# STM32MP25_CM33 register map
File version: 1.3
CPU: CM33 r0p1, little endian, MPU, FPU, vendor SysTick, 8 interrupt priority bits
Registers are 32-bit, read-write, reset 0x0 unless marked. A register's access mark holds for its fields unless they carry their own. Offsets are from the block's base; [hi:lo] are bit positions; lines under a group give offsets from that group; {n}, {i} and the like mark numbered series; 'fields as' and 'values as' point back to an identical list.

## ADC1 — ADC register block
Base 0x404E0000
Same registers: ADC2 0x404E0100, ADC1_S 0x504E0000, ADC2_S 0x504E0100
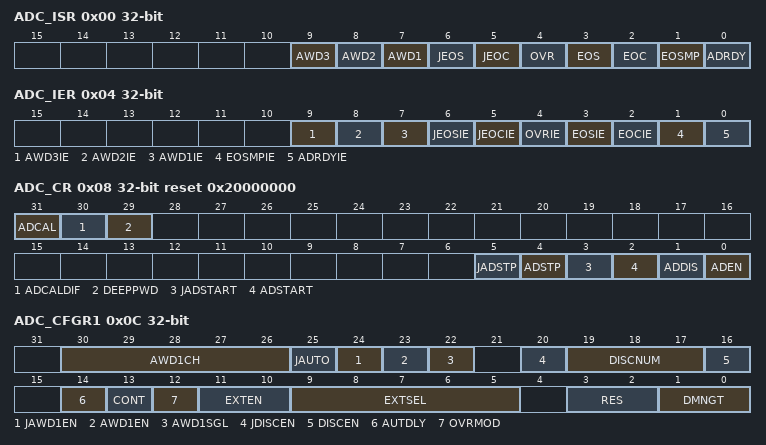
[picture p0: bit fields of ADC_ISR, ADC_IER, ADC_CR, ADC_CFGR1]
0x00 ADC_ISR — ADC interrupt and status register
  [9] AWD3 — Analog watchdog 3 flag This bit is set by hardware when the converted voltage crosses the values programmed in the fields LTR[22:0] and HTR[22:0] of ADC_AWD3LTR and ADC_AWD3HTR registers. It is cleared by software writing 1 to it.
    0=No analog watchdog 3 event occurred (or the flag event was already acknowledged and cleared by software); 1=Analog watchdog 3 event occurred
  [8] AWD2 — Analog watchdog 2 flag This bit is set by hardware when the converted voltage crosses the values programmed in the fields LTR[22:0] and HTR[22:0] of ADC_AWD2LTR and ADC_AWD2HTR registers. It is cleared by software writing 1 to it.
    0=No analog watchdog 2 event occurred (or the flag event was already acknowledged and cleared by software); 1=Analog watchdog 2 event occurred
  [7] AWD1 — Analog watchdog 1 flag This bit is set by hardware when the converted voltage crosses the values programmed in the fields LTR[22:0] and HTR[22:0] of ADC_AWD1LTR and ADC_AWD1HTR registers. It is cleared by software. writing 1 to it.
    0=No analog watchdog 1 event occurred (or the flag event was already acknowledged and cleared by software); 1=Analog watchdog 1 event occurred
  [6] JEOS — Injected channel end of sequence flag This bit is set by hardware at the end of the conversions of all injected channels in the group. It is cleared by software writing 1 to it.
    0=Injected conversion sequence not complete (or the flag event was already acknowledged and cleared by software); 1=Injected conversions complete
  [5] JEOC — Injected channel end of conversion flag This bit is set by hardware at the end of each injected conversion of a channel when a new data is available in the corresponding ADC_JDRy register. It is cleared by software writing 1 to it, or by reading the corresponding ADC_JDRy register
    0=Injected channel conversion not complete (or the flag event was already acknowledged and cleared by software); 1=Injected channel conversion complete
  [4] OVR — ADC overrun This bit is set by hardware when an overrun occurs on a regular channel (a new conversion has completed while the EOC flag was already set) or when adc_hclk clock is too slow to manage the data. It is cleared by software writing 1 to it.
    0=No overrun occurred (or the flag event was already acknowledged and cleared by software); 1=Overrun has occurred
  [3] EOS — End of regular sequence flag This bit is set by hardware at the end of the conversions of a regular sequence of channels. It is cleared by software writing 1 to it.
    0=Regular Conversions sequence not complete (or the flag event was already acknowledged and cleared by software); 1=Regular Conversions sequence complete
  [2] EOC — End of conversion flag This bit is set by hardware at the end of each regular conversion of a channel when a new data is available in the ADC_DR register. It is cleared by software writing 1 to it or by reading the ADC_DR register
    0=Regular channel conversion not complete (or the flag event was already acknowledged and cleared by software); 1=Regular channel conversion complete
  [1] EOSMP — End of sampling flag This bit is set by hardware during the conversion of any channel (only for regular channels), at the end of the sampling phase. Note: When the OVR flag is raised, the EOSMP flag is not generated correctly.
    0=not at the end of the sampling phase (or the flag event was already acknowledged and cleared by software); 1=End of sampling phase reached
  [0] ADRDY — ADC ready This bit is set by hardware after the ADC has been enabled (bit ADEN=1) and when the ADC reaches a state where it is ready to accept conversion requests. It is cleared by software writing 1 to it.
    0=ADC not yet ready to start conversion (or the flag event was already acknowledged and cleared by software); 1=ADC is ready to start conversion
0x04 ADC_IER — ADC interrupt enable register
  [9] AWD3IE — Analog watchdog 3 interrupt enable This bit is set and cleared by software to enable/disable the analog watchdog 2 interrupt. Note: The software is allowed to write this bit only when ADSTART=0 and JADSTART=0 (which ensures that no conversion is ongoing).
    0=Analog watchdog 3 interrupt disabled; 1=Analog watchdog 3 interrupt enabled
  [8] AWD2IE — Analog watchdog 2 interrupt enable This bit is set and cleared by software to enable/disable the analog watchdog 2 interrupt. Note: The software is allowed to write this bit only when ADSTART=0 and JADSTART=0 (which ensures that no conversion is ongoing).
    0=Analog watchdog 2 interrupt disabled; 1=Analog watchdog 2 interrupt enabled
  [7] AWD1IE — Analog watchdog 1 interrupt enable This bit is set and cleared by software to enable/disable the analog watchdog 1 interrupt. Note: The software is allowed to write this bit only when ADSTART=0 and JADSTART=0 (which ensures that no conversion is ongoing).
    0=Analog watchdog 1 interrupt disabled; 1=Analog watchdog 1 interrupt enabled
  [6] JEOSIE — End of injected sequence of conversions interrupt enable This bit is set and cleared by software to enable/disable the end of injected sequence of conversions interrupt. Note: The software is allowed to write this bit only when JADSTART=0 (which ensures that no injected conversion is ongoing).
    0=JEOS interrupt disabled; 1=JEOS interrupt enabled. An interrupt is generated when the JEOS bit is set.
  [5] JEOCIE — End of injected conversion interrupt enable This bit is set and cleared by software to enable/disable the end of an injected conversion interrupt. Note: The software is allowed to write this bit only when JADSTART=0 (which ensures that no injected conversion is ongoing).
    0=JEOC interrupt disabled; 1=JEOC interrupt enabled. An interrupt is generated when the JEOC bit is set.
  [4] OVRIE — Overrun interrupt enable This bit is set and cleared by software to enable/disable the Overrun interrupt of a regular conversion. Note: The software is allowed to write this bit only when ADSTART=0 (which ensures that no regular conversion is ongoing).
    0=Overrun interrupt disabled; 1=Overrun interrupt enabled. An interrupt is generated when the OVR bit is set.
  [3] EOSIE — End of regular sequence of conversions interrupt enable This bit is set and cleared by software to enable/disable the end of regular sequence of conversions interrupt. Note: The software is allowed to write this bit only when ADSTART=0 (which ensures that no regular conversion is ongoing).
    0=EOS interrupt disabled; 1=EOS interrupt enabled. An interrupt is generated when the EOS bit is set.
  [2] EOCIE — End of regular conversion interrupt enable This bit is set and cleared by software to enable/disable the end of a regular conversion interrupt. Note: The software is allowed to write this bit only when ADSTART=0 (which ensures that no regular conversion is ongoing).
    0=EOC interrupt disabled; 1=EOC interrupt enabled. An interrupt is generated when the EOC bit is set.
  [1] EOSMPIE — End of sampling flag interrupt enable for regular conversions This bit is set and cleared by software to enable/disable the end of the sampling phase interrupt for regular conversions. Note: The software is allowed to write this bit only when ADSTART=0 (which ensures that no regular conversion is ongoing).
    0=EOSMP interrupt disabled; 1=EOSMP interrupt enabled. An interrupt is generated when the EOSMP bit is set.
  [0] ADRDYIE — ADC ready interrupt enable This bit is set and cleared by software to enable/disable the ADC Ready interrupt. Note: The software is allowed to write this bit only when ADSTART=0 and JADSTART=0 (which ensures that no conversion is ongoing).
    0=ADRDY interrupt disabled; 1=ADRDY interrupt enabled. An interrupt is generated when the ADRDY bit is set.
0x08 ADC_CR reset 0x20000000 — ADC control register
  [31] ADCAL — ADC calibration This bit is set by software to enter ADC Calibration mode. Note: The software is allowed to update the calibration factor by writing ADC_CALFACT only when ADEN=1, ADCAL=1, ADSTART=0 and JADSTART=0 (ADC enabled, Calibration mode enabled and no conversion ongoing).
    0=Normal mode; 1=Calibration mode
  [30] ADCALDIF — Differential mode for calibration This bit is set and cleared by software to configure the single-ended or differential input mode for the calibration. Note: The software is allowed to write this bit only when the ADC is disabled and is not calibrating (ADCAL=0, JADSTART=0, JADSTP=0, ADSTART=0, ADSTP=0, ADDIS=0 and ADEN=0).
    0=Single-ended input calibration mode; 1=Differential input calibration mode
  [29] DEEPPWD — Deep-power-down enable This bit is set and cleared by software to put the ADC in Deep-power-down mode. Note: The software is allowed to write this bit only when the ADC is disabled (ADCAL=0 and ADEN=0).
    0=ADC not in Deep-power down; 1=ADC in Deep-power-down (default reset state)
  [5] JADSTP — ADC stop of injected conversion command This bit is set by software to stop and discard an ongoing injected conversion (JADSTP command). It is cleared by hardware when the conversion is effectively discarded and the ADC injected sequence and triggers can be reconfigured. The ADC is then ready to accept a new start of injected conversions (JADSTART command). When a software trigger is used, JADSTART bit is cleared by hardware, but JADSTP bit must be programmed to reconfigure the ADC. Note: In auto-injection mode (JAUTO=1), setting ADSTP bit aborts both regular and injected conversions (do not use JADSTP).
    0=No ADC stop injected conversion command ongoing; 1=Write 1 to stop injected conversions ongoing. Read 1 means that an ADSTP command is in progress.
  [4] ADSTP — ADC stop of regular conversion command This bit is set by software to stop and discard an ongoing regular conversion (ADSTP Command). It is cleared by hardware when the conversion is effectively discarded. and the ADC regular sequence and triggers can be re-configured. The ADC is then ready to accept a new start of regular conversions (ADSTART command). When a software trigger is used, ADSTART bit is cleared by hardware. However it is necessary to write ADSTP bit to reconfigure the ADC. Note: In auto-injection mode (JAUTO=1), setting ADSTP bit aborts both regular and injected conversions (do not use ADSTP).
    0=No ADC stop regular conversion command ongoing; 1=Write 1 to stop regular conversions ongoing. Read 1 means that an ADSTP command is in progress.
  [3] JADSTART — ADC start of injected conversion This bit is set by software to start ADC conversion of injected channels. Depending on the configuration bits JEXTEN[1:0], a conversion starts immediately (software trigger configuration) or once an injected hardware trigger event occurs (hardware trigger configuration). This bit is cleared by hardware: In single conversion mode when software trigger is selected (JEXTSEL=0x0 and JDISEN=1): at the assertion of the end of injected conversion sequence (JEOS) flag. In all cases: after the execution of the JADSTP command, at the same time that JADSTP is cleared by hardware. Note: The software is allowed to set JADSTART only when ADEN=1,ADDIS=0 and JAUTO= 0 (ADC is enabled and there is no pending request to disable the ADC). Note: In auto-injection mode (JAUTO=1), regular and auto-injected conversions are started by setting ADSTART bit (JADSTART must be kept cleared).
    0=No ADC injected conversion is ongoing; 1=Write 1 to start injected conversions. Read 1 means that the ADC is operating and eventually converting an injected channel.
  [2] ADSTART — ADC start of regular conversion This bit is set by software to start ADC conversion of regular channels. Depending on the configuration bits EXTEN[1:0], a conversion starts immediately (software trigger configuration) or once a regular hardware trigger event occurs (hardware trigger configuration). This bit is cleared by hardware: in single conversion mode when software trigger is selected (EXTSEL=0x0 and DISEN=1): at the assertion of the end of regular conversion sequence (EOS) flag. in all cases: after the execution of the ADSTP command, at the same time that ADSTP is cleared by hardware. Note: The software is allowed to set ADSTART only when ADEN=1 and ADDIS=0 (ADC is enabled and there is no pending request to disable the ADC). Note: In auto-injection mode (JAUTO=1), regular and auto-injected conversions are started by setting ADSTART bit (JADSTART must be kept cleared)
    0=No ADC regular conversion is ongoing; 1=Write 1 to start regular conversions. Read 1 means that the ADC is operating and eventually converting a regular channel.
  [1] ADDIS — ADC disable command This bit is set by software to disable the ADC (ADDIS command) and place it into power-down state (OFF state). It is cleared by hardware once the ADC is effectively disabled (ADEN is also cleared by hardware at this time). Note: The software is allowed to set ADDIS only when ADEN=1, ADDIS=0 and both ADSTART=0 and JADSTART=0 (which ensures that no conversion is ongoing).
    0=no ADDIS command ongoing; 1=Write 1 to disable the ADC. Read 1 means that an ADDIS command is in progress.
  [0] ADEN — ADC enable control This bit is set by software to enable the ADC. The ADC is effectively ready to operate once the ADRDY flag has been set. It is cleared by hardware when the ADC is disabled, after the execution of the ADDIS command. Note: The software is allowed to set ADEN only when all the bits of ADC_CR registers are cleared (ADCAL=0, JADSTART=0, ADSTART=0, ADSTP=0, ADDIS=0 and ADEN=0).
    0=ADC is disabled (OFF state); 1=Write 1 to enable the ADC
0x0C ADC_CFGR1 — ADC configuration register
  [30:26] AWD1CH — Analog watchdog 1 channel selection These bits are set and cleared by software. They select the input channel to be guarded by the analog watchdog. ..... others: reserved, must not be used Note: Some channels are not connected physically. Keep the corresponding AWD1CH[4:0] setting to the reset value. Note: The channel selected by AWD1CH must be also selected into the SQRi or JSQRi registers. Note: The software is allowed to write these bits only when ADSTART=0 and JADSTART=0 (which ensures that no conversion is ongoing).
    0=ADC analog input channel 0 monitored by AWD1; 1=ADC analog input channel 1 monitored by AWD1; 19=ADC analog input channel 19 monitored by AWD1
  [25] JAUTO — Automatic injected group conversion This bit is set and cleared by software to enable/disable automatic injected group conversion after regular group conversion. Note: The software is allowed to write this bit only when ADSTART=0 and JADSTART=0 (which ensures that no regular nor injected conversion is ongoing).
    0=Automatic injected group conversion disabled; 1=Automatic injected group conversion enabled
  [24] JAWD1EN — Analog watchdog 1 enable on injected channels This bit is set and cleared by software Note: The software is allowed to write this bit only when JADSTART=0 (which ensures that no injected conversion is ongoing).
    0=Analog watchdog 1 disabled on injected channels; 1=Analog watchdog 1 enabled on injected channels
  [23] AWD1EN — Analog watchdog 1 enable on regular channels This bit is set and cleared by software Note: The software is allowed to write this bit only when ADSTART=0 (which ensures that no regular conversion is ongoing).
    0=Analog watchdog 1 disabled on regular channels; 1=Analog watchdog 1 enabled on regular channels
  [22] AWD1SGL — Enable the watchdog 1 on a single channel or on all channels This bit is set and cleared by software to enable the analog watchdog on the channel identified by the AWD1CH[4:0] bits or on all the channels Note: The software is allowed to write these bits only when ADSTART=0 and JADSTART=0 (which ensures that no conversion is ongoing).
    0=Analog watchdog 1 enabled on all channels; 1=Analog watchdog 1 enabled on a single channel
  [20] JDISCEN — Discontinuous mode on injected channels This bit is set and cleared by software to enable/disable discontinuous mode on the injected channels of a group. Note: The software is allowed to write this bit only when JADSTART=0 (which ensures that no injected conversion is ongoing). Note: It is not possible to use auto-injection mode and discontinuous mode simultaneously: the DISCEN and JDISCEN bits must be kept cleared by software when JAUTO is set.
    0=Discontinuous mode on injected channels disabled; 1=Discontinuous mode on injected channels enabled
  [19:17] DISCNUM — Discontinuous mode channel count These bits are written by software to define the number of regular channels to be converted in discontinuous mode, after receiving an external trigger. ... Note: The software is allowed to write these bits only when ADSTART=0 (which ensures that no regular conversion is ongoing).
    0=1 channel; 1=2 channels; 7=8 channels
  [16] DISCEN — Discontinuous mode for regular channels This bit is set and cleared by software to enable/disable discontinuous mode for regular channels. Note: It is not possible to have both discontinuous mode and continuous mode enabled: DISCEN and CONT cannot both be set (DISCEN takes priority). Note: It is not possible to use auto-injection mode and discontinuous mode simultaneously: the DISCEN and JDISCEN bits must be kept cleared by software when JAUTO is set. Note: The software is allowed to write this bit only when ADSTART=0 (which ensures that no regular conversion is ongoing).
    0=Discontinuous mode for regular channels disabled; 1=Discontinuous mode for regular channels enabled
  [14] AUTDLY — Delayed conversion mode This bit is set and cleared by software to enable/disable the auto-delayed conversion mode.sup./sup Note: The software is allowed to write this bit only when ADSTART=0 and JADSTART=0 (which ensures that no conversion is ongoing).
    0=Auto-delayed conversion mode off; 1=Auto-delayed conversion mode on
  [13] CONT — Single / continuous conversion mode for regular conversions This bit is set and cleared by software. If it is set, regular conversion takes place continuously until it is cleared. Note: It is not possible to have both discontinuous mode and continuous mode enabled: DISCEN and CONT cannot both be set (DISCEN takes priority). Note: The software is allowed to write this bit only when ADSTART=0 (which ensures that no regular conversion is ongoing).
    0=Single conversion mode; 1=Continuous conversion mode
  [12] OVRMOD — Overrun mode This bit is set and cleared by software and configure the way data overrun is managed. Note: The software is allowed to write this bit only when ADSTART=0 (which ensures that no regular conversion is ongoing).
    0=ADC_DR register is preserved with the old data when an overrun is detected; 1=ADC_DR register is overwritten with the last conversion result when an overrun is detected
  [11:10] EXTEN — External trigger enable and polarity selection for regular channels These bits are set and cleared by software to select the external trigger polarity and enable the trigger of a regular group. Note: The software is allowed to write these bits only when ADSTART=0 (which ensures that no regular conversion is ongoing).
    0=Hardware trigger detection disabled (conversions can be launched by software); 1=Hardware trigger detection on the rising edge; 2=Hardware trigger detection on the falling edge; 3=Hardware trigger detection on both the rising and falling edges
  [9:5] EXTSEL — External trigger selection for regular group These bits select the external event used to trigger the start of conversion of a regular group: ... Note: The software is allowed to write these bits only when ADSTART=0 (which ensures that no regular conversion is ongoing).
    {v}=adc_ext_trg{v} (v=0..7); 31=adc_ext_trg31
  [3:2] RES — Data resolution These bits are written by software to select the resolution of the conversion. Note: The software is allowed to write these bits only when ADSTART=0 and JADSTART=0 (which ensures that no conversion is ongoing).
    0=12-bit; 1=10-bit; 2=8-bit; 3=6-bit
  [1:0] DMNGT — Data management configuration These bits are set and cleared by software to select how the ADC interface output data are managed. Note: The software is allowed to write these bits only when ADSTART=0 and JADSTART=0 (which ensures that no conversion is ongoing).
    0=Regular conversion data stored in DR only; 1=DMA one-shot mode selected; 2=MDF mode detected; 3=DMA circular mode selected
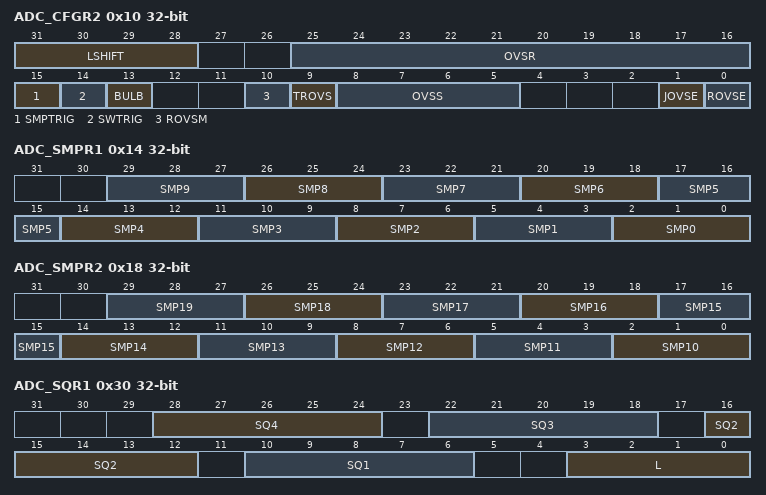
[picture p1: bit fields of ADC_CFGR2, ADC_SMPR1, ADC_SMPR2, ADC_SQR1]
0x10 ADC_CFGR2 — ADC configuration register 2
  [31:28] LSHIFT — Left shift factor This bit field is set and cleared by software to define the left shifting applied to the final result with or without oversampling. Note: The software is allowed to write this bit only when ADSTART=0 and JADSTART=0 (which ensures that no conversion is ongoing).
    0=No left shift; {v}={v}-bit left shift (v=1..15)
  [25:16] OVSR — Oversampling ratio This bit field is set and cleared by software to define the oversampling ratio. ... Note: The software is allowed to write this bit only when ADSTART=0 and JADSTART=0 (which ensures that no conversion is ongoing).
    0=1x (no oversampling); 1=2x
  [15] SMPTRIG — Sampling time control trigger mode This bit is set and cleared by software to enable the sampling time control trigger mode. If EXTEN[1:0] bits are set to 01, the sampling time starts on the trigger rising edge, and the conversion starts on the trigger falling edge. The SMPTRIG bit must not be set when the SMPTRIG bit is set. When EXTEN[1:0] bits are set to 00, set SWTRIG to start the sampling and clear the BULB bit to start the conversion. Note: The software is allowed to write this bit only when ADSTART=0 and JADSTART=0 (which ensures that no conversion is ongoing). When the discontinuous mode is used, only DISCNUM[2:0]=000 configuration is compatible with sampling time control trigger mode.
    0=Sampling time control trigger mode disabled; 1=Sampling time control trigger mode enabled
  [14] SWTRIG — Software trigger bit for sampling time control trigger mode This bit is set and cleared by software to trigger the conversion in sampling time control trigger mode. Note: The software is allowed to write this bit only when ADSTART=0, JADSTART=0 (which ensures that no conversion is ongoing), SMPTRIG=1, and EXTEN[0:1]=00.
    0=Software trigger starts the conversion for sampling time control trigger mode; 1=Software trigger starts the sampling for sampling time control trigger mode
  [13] BULB — Bulb sampling mode This bit is set and cleared by software to enable the bulb sampling mode. BULB bit must not be set when the SWTRIG bit is set. The very first ADC conversion is performed with the sampling time specified in SMPx bits. Note: The software is allowed to write this bit only when ADSTART=0 and JADSTART=0 (which ensures that no conversion is ongoing). When the discontinuous mode is used, only DISCNUM[2:0]=000 configuration is compatible with bulb mode.
    0=Bulb sampling mode disabled; 1=Bulb sampling mode enabled. The sampling period starts just after the previous end of conversion.
  [10] ROVSM — Regular oversampling mode This bit is set and cleared by software to select the regular oversampling mode. Note: The software is allowed to write this bit only when ADSTART=0 and JADSTART=0 (which ensures that no conversion is ongoing). It is recommended to clear both JOVSE and GCOMP when ROVSM=0.
    0=Continued mode: When injected conversions are triggered, the oversampling is temporary stopped and continued after the injection sequence (oversampling buffer is maintained during injected sequence); 1=Resumed mode: When injected conversions are triggered, the current oversampling is aborted and resumed from start after the injection sequence (oversampling buffer is zeroed by injected sequence start)
  [9] TROVS — Triggered regular oversampling This bit is set and cleared by software to enable triggered oversampling Note: The software is allowed to write this bit only when ADSTART=0 and JADSTART=0 (which ensures that no conversion is ongoing).
    0=All oversampled conversions for a channel are done consecutively following a trigger; 1=Each oversampled conversion for a channel needs a new trigger
  [8:5] OVSS — Oversampling shift This bit field is set and cleared by software to define the right shifting applied to the raw oversampling result. Other: reserved, must not be used Note: The software is allowed to write this bit only when ADSTART=0 and JADSTART=0 (which ensures that no conversion is ongoing).
    0=No shift; {v}={v}-bit shift (v=1..10)
  [1] JOVSE — Injected oversampling enable This bit is set and cleared by software to enable injected oversampling. Note: The software is allowed to write this bit only when JADSTART=0 (which ensures that no conversion is ongoing)
    0=Injected oversampling disabled; 1=Injected oversampling enabled
  [0] ROVSE — Regular oversampling enable This bit is set and cleared by software to enable regular oversampling. Note: The software is allowed to write this bit only when ADSTART=0 (which ensures that no conversion is ongoing)
    0=Regular oversampling disabled; 1=Regular oversampling enabled
0x14 ADC_SMPR1 — ADC sample time register 1
  [all] fields
    0=1.5 ADC clock cycles; 1=2.5 ADC clock cycles; 2=6.5 ADC clock cycles; 3=11.5 ADC clock cycles; 4=23.5 ADC clock cycles; 5=46.5 ADC clock cycles; 6=246.5 ADC clock cycles; 7=1499.5 ADC clock cycles
  [3n+2:3n] SMP{n} (n=0..9) — Channel x sampling time selection (x=9 to 0) These bits are written by software to select the sampling time individually for each channel. During sample cycles, the channel selection bits must remain unchanged. Note: The software is allowed to write these bits only when ADSTART=0 and JADSTART=0 (which ensures that no conversion is ongoing). Note: Some channels are not connected physically. Keep the corresponding SMPx[2:0] setting to the reset value.
0x18 ADC_SMPR2 — ADC sample time register 2
  [all] fields
    values as the fields of ADC_SMPR1
  [3n-28:3n-30] SMP{n} (n=10..19) — Channel x sampling time selection (x=19 to 10) These bits are written by software to select the sampling time individually for each channel. During sampling cycles, the channel selection bits must remain unchanged. Note: The software is allowed to write these bits only when ADSTART=0 and JADSTART=0 (which ensures that no conversion is ongoing). Note: Some channels are not connected physically. Keep the corresponding SMPx[2:0] setting to the reset value.
0x1C ADC_PCSEL — ADC channel preselection register
  [19:0] PCSEL — Channel i (VsubINP/sub[i]) preselection These bits are written by software to preselect the input channel I/O to be converted. Note: The software is allowed to write these bits only when ADSTART=0 and JADSTART=0 (which ensures that no conversion is ongoing).
    0=Input channel i (VsubINP/sub[i]) is not preselected for conversion, the result of the ADC conversion for this channel is wrong; 1=Input channel i (VsubINP/sub[i]) is preselected for conversion
0x30 ADC_SQR1 — ADC regular sequence register 1
  [28:24] SQ4 — 4th conversion in regular sequence These bits are written by software with the channel number (0 to 19) assigned as the 4th in the regular conversion sequence. Note: The software is allowed to write these bits only when ADSTART = 0 (which ensures that no regular conversion is ongoing).
  [22:18] SQ3 — 3rd conversion in regular sequence These bits are written by software with the channel number (0 to 19) assigned as the 3rd in the regular conversion sequence. Note: The software is allowed to write these bits only when ADSTART=0 (which ensures that no regular conversion is ongoing).
  [16:12] SQ2 — 2nd conversion in regular sequence These bits are written by software with the channel number (0 to 19) assigned as the 2nd in the regular conversion sequence. Note: The software is allowed to write these bits only when ADSTART=0 (which ensures that no regular conversion is ongoing).
  [10:6] SQ1 — 1st conversion in regular sequence These bits are written by software with the channel number (0 to 19) assigned as the 1st in the regular conversion sequence. Note: The software is allowed to write these bits only when ADSTART=0 (which ensures that no regular conversion is ongoing).
  [3:0] L — Regular channel sequence length These bits are written by software to define the total number of conversions in the regular channel conversion sequence. ... Note: The software is allowed to write these bits only when ADSTART=0 (which ensures that no regular conversion is ongoing).
    0=1 conversion; 1=2 conversions; 15=16 conversions
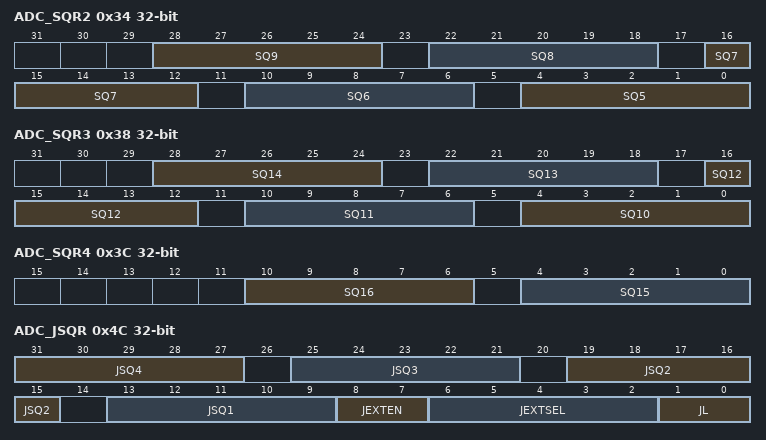
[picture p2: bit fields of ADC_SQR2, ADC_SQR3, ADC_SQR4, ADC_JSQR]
0x34 ADC_SQR2 — ADC regular sequence register 2
  [28:24] SQ9 — 9th conversion in regular sequence These bits are written by software with the channel number (0 to 19) assigned as the 9th in the regular conversion sequence. Note: The software is allowed to write these bits only when ADSTART=0 (which ensures that no regular conversion is ongoing).
  [22:18] SQ8 — 8th conversion in regular sequence These bits are written by software with the channel number (0 to 19) assigned as the 8th in the regular conversion sequence Note: The software is allowed to write these bits only when ADSTART=0 (which ensures that no regular conversion is ongoing).
  [16:12] SQ7 — 7th conversion in regular sequence These bits are written by software with the channel number (0 to 19) assigned as the 7th in the regular conversion sequence. Note: The software is allowed to write these bits only when ADSTART=0 (which ensures that no regular conversion is ongoing).
  [10:6] SQ6 — 6th conversion in regular sequence These bits are written by software with the channel number (0 to 19) assigned as the 6th in the regular conversion sequence. Note: The software is allowed to write these bits only when ADSTART=0 (which ensures that no regular conversion is ongoing).
  [4:0] SQ5 — 5th conversion in regular sequence These bits are written by software with the channel number (0 to 19) assigned as the 5th in the regular conversion sequence. Note: The software is allowed to write these bits only when ADSTART=0 (which ensures that no regular conversion is ongoing).
0x38 ADC_SQR3 — ADC regular sequence register 3
  [6n-56:6n-60] SQ{n} (n=10..14) — {n}th conversion in regular sequence These bits are written by software with the channel number (0 to 19) assigned as the {n}th in the regular conversion sequence. Note: The software is allowed to write these bits only when ADSTART=0 (which ensures that no regular conversion is ongoing).
0x3C ADC_SQR4 — ADC regular sequence register 4
  [10:6] SQ16 — 16th conversion in regular sequence These bits are written by software with the channel number (0 to 19) assigned as the 16th in the regular conversion sequence. Note: The software is allowed to write these bits only when ADSTART=0 (which ensures that no regular conversion is ongoing).
  [4:0] SQ15 — 15th conversion in regular sequence These bits are written by software with the channel number (0 to 19) assigned as the 15th in the regular conversion sequence. Note: The software is allowed to write these bits only when ADSTART=0 (which ensures that no regular conversion is ongoing).
0x40 ADC_DR ro — ADC regular data register
  [31:0] RDATA — Regular data converted These bits are read-only. They contain the conversion result from the last converted regular channel. The data are left- or right-aligned as described in Section41.4.26: Data management.
0x4C ADC_JSQR — ADC injected sequence register
  [31:27] JSQ4 — 4th conversion in the injected sequence These bits are written by software with the channel number (0 to 19) assigned as the 4th in the injected conversion sequence. Note: The software is allowed to write these bits only when JADSTART=0 (which ensures that no injected conversion is ongoing).
  [25:21] JSQ3 — 3rd conversion in the injected sequence These bits are written by software with the channel number (0 to 19) assigned as the 3rd in the injected conversion sequence. Note: The software is allowed to write these bits only when JADSTART=0 (which ensures that no injected conversion is ongoing).
  [19:15] JSQ2 — 2nd conversion in the injected sequence These bits are written by software with the channel number (0 to 19) assigned as the 2nd in the injected conversion sequence. Note: The software is allowed to write these bits only when JADSTART=0 (which ensures that no injected conversion is ongoing).
  [13:9] JSQ1 — 1st conversion in the injected sequence These bits are written by software with the channel number (0 to 19) assigned as the 1st in the injected conversion sequence. Note: The software is allowed to write these bits only when JADSTART=0 (which ensures that no injected conversion is ongoing).
  [8:7] JEXTEN — External trigger enable and polarity selection for injected channels These bits are set and cleared by software to select the external trigger polarity and enable the trigger of an injected group. Note: The software is allowed to write these bits only when JADSTART=0 (which ensures that no injected conversion is ongoing).
    values as ADC_CFGR1.EXTEN
  [6:2] JEXTSEL — External trigger selection for injected group These bits select the external event used to trigger the start of conversion of an injected group: ... Note: The software is allowed to write these bits only when JADSTART=0 (which ensures that no injected conversion is ongoing).
    {v}=adc_jext_trg{v} (v=0..7); 31=adc_jext_trg31
  [1:0] JL — Injected channel sequence length These bits are written by software to define the total number of conversions in the injected channel conversion sequence. Note: The software is allowed to write these bits only when JADSTART=0 (which ensures that no injected conversion is ongoing).
    0=1 conversion; 1=2 conversions; 2=3 conversions; 3=4 conversions
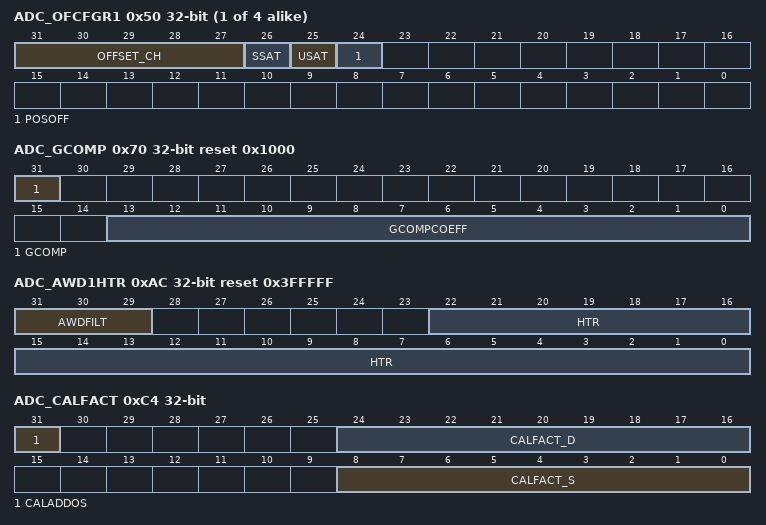
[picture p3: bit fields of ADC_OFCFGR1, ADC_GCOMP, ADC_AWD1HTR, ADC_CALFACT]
{0x4C+4i} ADC_OFCFGR{i} (i=1..4) — ADC offset {i} configuration register
  [31:27] OFFSET_CH — Channel selection for the data offset y These bits are written by software to define the channel to which the offset programmed in bits OFFSET[21:0] applies. Note: The software is allowed to write these bits only when ADSTART=0 and JADSTART=0 (which ensures that no conversion is ongoing). Note: Some channels are not connected physically and must not be selected for the data offset y.
  [26] SSAT — Signed saturation enable This bit is set and cleared by software to enable the signed saturation feature.(see Section: Data register, data alignment and offset (ADC_DR, ADC_JDRy, OFFSETy, OFFSETy_CH, OVSS, LSHIFT, USAT, SSAT, POSOFF)). Note: The software is allowed to write these bits only when ADSTART=0 and JADSTART=0 (which ensures that no conversion is ongoing).
    0=Offset is subtracted maintaining the data integrity and extending converted data size (13-bit signed format); 1=Offset is subtracted and result is saturated to maintain the converted data size
  [25] USAT — Unsigned saturation enable This bit is set and cleared by software to enable the unsigned saturation feature. Note: The software is allowed to write these bits only when ADSTART= and JADSTART=0 (which ensures that no conversion is ongoing).
    0=Offset is subtracted maintaining the data integrity; 1=Offset is subtracted and result is saturated to maintain the converted data size
  [24] POSOFF — Positive offset enable This bit is set and cleared by software to enable the positive offset Note: The software is allowed to write these bits only when ADSTART=0 and JADSTART=0 (which ensures that no conversion is ongoing).
    0=Negative offset; 1=Positive offset
{0x5C+4i} ADC_OFR{i} (i=1..4) — ADC offset {i} register
  [21:0] OFFSET — Data offset y for the channel programmed in OFFSETy_CH[4:0] bits These bits are written by software to define the offset y to be subtracted from the raw converted data when converting a channel (can be regular or injected). The channel to which applies the data offset y must be programmed in the OFFSETy_CH[4:0] bits. The conversion result can be read from in the ADC_DR (regular conversion) or from in the ADC_JDRyi registers (injected conversion). Note: The software is allowed to write these bits only when ADSTART=0 and JADSTART=0 (which ensures that no conversion is ongoing).
0x70 ADC_GCOMP reset 0x1000 — ADC gain compensation register
  [31] GCOMP — Gain compensation mode This bit is set and cleared by software to enable the Gain compensation mode. Note: The software is allowed to write this bit only when ADSTART=0 and JADSTART=0 (which ensure that no conversion is ongoing)
    0=Regular ADC operation mode; 1=Gain compensation enabled and applied on all channels
  [13:0] GCOMPCOEFF — Gain compensation coefficient These bits are set and cleared by software to program the gain compensation coefficient. ... ... The coefficient is divided by 4096 to get the gain factor ranging from 0 to 3.9999756 Note: This gain compensation is only applied when GCOMP bit is set. Note: The software is allowed to write this bit only when ADSTART =0 and JADSTART=0 (which ensure that no conversion is ongoing).
    0x800=gain factor of 0.5; 0x1000=gain factor of 1; 0x2000=gain factor of 2; 0x3000=gain factor of 3
{0x7C+4i} ADC_JDR{i} ro (i=1..4) — ADC injected channel {i} data register
  [31:0] JDATA — Injected data These bits are read-only. They contain the conversion result from injected channel y. The data are left- or right-aligned as described in Section41.4.26: Data management.
0xA0 ADC_AWD2CR — ADC Analog Watchdog 2 Configuration Register
  [19:0] AWDCH — Analog watchdog 2 channel selection These bits are set and cleared by software. They enable and select the input channels to be guarded by the analog watchdog 2. AWDCH[i] = 0: ADC analog input channel i is not monitored by AWD2 AWDCH[i] = 1: ADC analog input channel i is monitored by AWD2 When AWDCH[19:0] = 000..0, the analog Watchdog 2 is disabled Note: The channels selected by AWDCH must be also selected in the SQRi or JSQRi registers. Note: The software is allowed to write these bits only when ADSTART=0 and JADSTART=0 (which ensures that no conversion is ongoing). Note: Some channels are not connected physically and must not be selected for the analog watchdog.
0xA4 ADC_AWD3CR — ADC Analog Watchdog 3 Configuration Register
  [19:0] AWDCH — Analog watchdog 3 channel selection These bits are set and cleared by software. They enable and select the input channels to be guarded by the analog watchdog 3. AWDCH[i] = 0: ADC analog input channel i is not monitored by AWD3 AWDCH[i] = 1: ADC analog input channel i is monitored by AWD3 When AWDCH[19:0] = 000..0, the analog Watchdog 3 is disabled Note: The channels selected by AWDCH must be also selected in the SQRi or JSQRi registers. Note: The software is allowed to write these bits only when ADSTART=0 and JADSTART=0 (which ensures that no conversion is ongoing). Note: Some channels are not connected physically and must not be selected for the analog watchdog.
0xA8 ADC_AWD1LTR — ADC analog watchdog 1 lower threshold register
  [22:0] LTR — Analog watchdog 1 lower threshold These bits are set and cleared by software to define the lower threshold for analog watchdog 1. Refer to Section41.4.29: Analog window watchdog (AWD1EN, JAWD1EN, AWD1SGL, AWD1CH, AWDCH of ADC_AWD2CR and ADC_AWD3CR, HTR, LTR, AWDFILT).
0xAC ADC_AWD1HTR reset 0x3FFFFF — ADC analog watchdog 1 higher threshold register
  [31:29] AWDFILT — Analog watchdog filtering parameter These bits are set and cleared by software. ...
    0=No filtering, one detection generates an AWDx flag or an interrupt; 1=two consecutive detections generate an AWDx flag or an interrupt; 7=Eight consecutive detections generate an AWDx flag or an interrupt
  [22:0] HTR — Analog watchdog 1 higher threshold These bits are set and cleared by software to define the higher threshold for analog watchdog 1. Refer to Analog windows watchdog section.
0xB0 ADC_AWD2LTR — ADC analog watchdog 2 lower threshold register
  [22:0] LTR — Analog watchdog 2 lower threshold These bits are set and cleared by software to define the lower threshold for analog watchdog 2. Refer to Analog windows watchdog section.
0xB4 ADC_AWD2HTR reset 0x3FFFFF — ADC analog watchdog 2 higher threshold register
  [22:0] HTR — Analog watchdog 2 higher threshold These bits are set and cleared by software to define the higher threshold for analog watchdog 2. Refer to Analog windows watchdog section.
0xB8 ADC_AWD3LTR — ADC analog watchdog 3 lower threshold register
  [22:0] LTR — Analog watchdog 3 lower threshold These bits are set and cleared by software to define the lower threshold for analog watchdog 3. Refer to Analog windows watchdog section.
0xBC ADC_AWD3HTR reset 0x3FFFFF — ADC analog watchdog 3 higher threshold register
  [22:0] HTR — Analog watchdog 3 higher threshold These bits are set and cleared by software to define the higher threshold for analog watchdog 3. Refer to Analog windows watchdog section.
0xC0 ADC_DIFSEL — ADC differential mode selection register
  [19:0] DIFSEL — Differential mode for channels 19 to 0. These bits are set and cleared by software. They allow to select if a channel is configured as single-ended or differential mode. DIFSEL[i] = 0: ADC analog input channel is configured in single-ended mode DIFSEL[i] = 1: ADC analog input channel i is configured in differential mode Note: The DIFSEL bits corresponding to channels that are either connected to a single-ended I/O port or to an internal channel must be kept their reset value (single-ended input mode). Note: The software is allowed to write these bits only when ADSTART=0 and JADSTART=0 (which ensures that no conversion is ongoing).
0xC4 ADC_CALFACT — ADC calibration factors
  [31] CALADDOS — Calibration additional offset This bit is set by software to add a positive offset at the input stage of ADC for calibration purpose. Note: The software is allowed to write these bits only when ADEN=1, ADCAL=1, ADSTART=0, and JADSTART=0 (ADC is enabled, no calibration is ongoing and no conversion is ongoing).
    0=Calibration additional positive offset disabled; 1=Calibration additional positive offset enabled
  [24:16] CALFACT_D — Calibration factors in differential mode These bits are written by hardware or by software. Once a differential input calibration is complete, they are updated by hardware with the calibration factors. The software can write these bits with a new calibration factor. If the new calibration factor is different from the current one stored in the analog ADC, it is applied once a new differential conversion is launched. Note: The software is allowed to write these bits only when ADEN=1, ADCAL=1, ADSTART=0 and JADSTART=0 (ADC is enabled, no calibration is ongoing and no conversion is ongoing).
  [8:0] CALFACT_S — Calibration factors In single-ended mode These bits are written by hardware or by software. Once a single-ended input calibration is complete, they are updated by hardware with the calibration factors. The software can write these bits with a new calibration factor. If the new calibration factor is different from the current one stored in the analog ADC, it is applied once a new single-ended conversion is launched. Note: The software is allowed to write these bits only when ADEN=1, ADCAL=1, ADSTART=0 and JADSTART=0 (ADC is enabled, no calibration is ongoing and no conversion is ongoing). Note: This bit can only be cleared by a power-on reset.
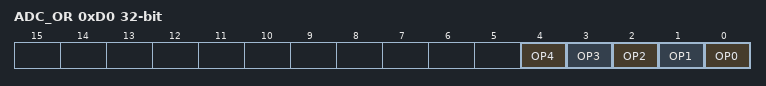
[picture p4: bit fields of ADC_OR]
0xD0 ADC_OR — ADC option register
  [4] OP4 — Option bit 4 This bit is set and cleared by software to enable/disable the VsubDDGPU/sub channel. Note: This bit is only available in ADC2 and ADC3.
    0=VsubDDGPU/sub channel disabled; 1=VsubDDGPU/sub channel enabled
  [3] OP3 — Option bit 3 This bit is set and cleared by software to enable/disable the VsubDDCPU/sub channel. Note: This bit is only available in ADC2 and ADC3
    0=VsubDDCPU/sub channel disabled; 1=VsubDDCPU/sub channel enabled
  [2] OP2 — Option bit 2 This bit is set and cleared by software to enable/disable the VsubDDCORE/sub channel. Note: This bit is only available in ADC2 and ADC3.
    0=VsubDDCORE/sub channel disabled; 1=VsubDDCORE/sub channel enabled
  [1] OP1 — Option bit 1 This bit is set and cleared by software to choose the ADC bandgap source The software is allowed to write this bit only when ADC is disabled.
    0=ADC internal bandgap disabled; 1=ADC internal bandgap enabled
  [0] OP0 — Option bit 0 This bit is set and cleared by software to enable the internal reference buffer. The software is allowed to write this bit only when ADC is disabled.
    0=ADC internal reference voltage buffer disabled; 1=ADC internal reference voltage buffer enabled
